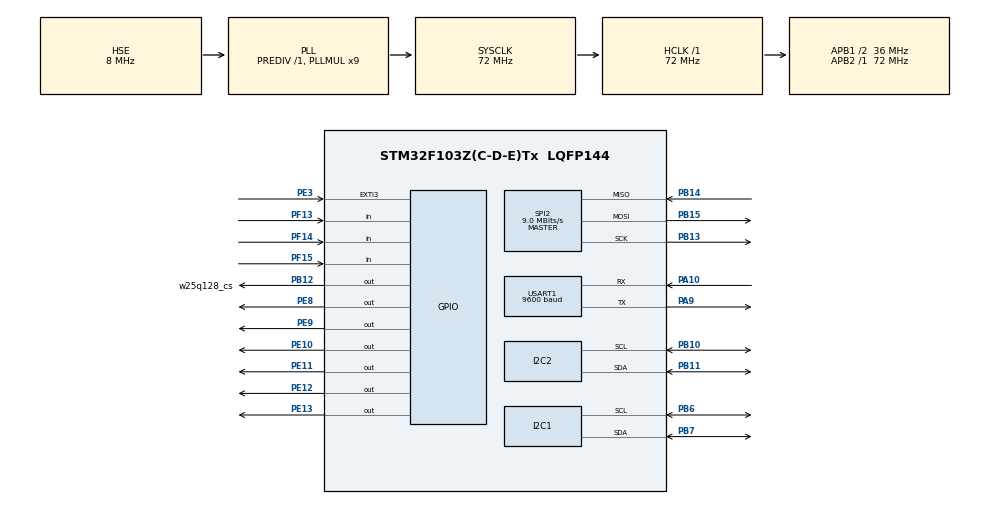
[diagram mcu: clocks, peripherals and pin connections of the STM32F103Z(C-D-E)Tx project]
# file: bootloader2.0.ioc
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Mcu.Family=STM32F1
Mcu.Name=STM32F103Z(C-D-E)Tx
Mcu.Package=LQFP144
NVIC.EXTI3_IRQn=true\:0\:0\:false\:false\:true\:true\:true\:true
NVIC.PriorityGroup=NVIC_PRIORITYGROUP_4
NVIC.TIM4_IRQn=true\:0\:0\:false\:false\:true\:true\:true\:true
NVIC.TIM7_IRQn=true\:15\:0\:false\:false\:true\:false\:true\:true
NVIC.TimeBase=TIM7_IRQn
NVIC.TimeBaseIP=TIM7
NVIC.USART1_IRQn=true\:0\:0\:false\:false\:true\:true\:true\:true
OSC_IN.Mode=HSE-External-Oscillator
OSC_IN.Signal=RCC_OSC_IN
OSC_OUT.Mode=HSE-External-Oscillator
OSC_OUT.Signal=RCC_OSC_OUT
PA10.Mode=Asynchronous
PA10.Signal=USART1_RX
PA13.Mode=JTAG_4_pins
PA13.Signal=SYS_JTMS-SWDIO
PA14.Mode=JTAG_4_pins
PA14.Signal=SYS_JTCK-SWCLK
PA15.Mode=JTAG_4_pins
PA15.Signal=SYS_JTDI
PA9.Mode=Asynchronous
PA9.Signal=USART1_TX
PB10.Mode=I2C
PB10.Signal=I2C2_SCL
PB11.Mode=I2C
PB11.Signal=I2C2_SDA
PB12.GPIO_Label=w25q128_cs
PB12.GPIO_Speed=GPIO_SPEED_FREQ_HIGH
PB12.PinState=GPIO_PIN_SET
PB12.Signal=GPIO_Output
PB13.Mode=Full_Duplex_Master
PB13.Signal=SPI2_SCK
PB14.Mode=Full_Duplex_Master
PB14.Signal=SPI2_MISO
PB15.Mode=Full_Duplex_Master
PB15.Signal=SPI2_MOSI
PB3.Mode=JTAG_4_pins
PB3.Signal=SYS_JTDO-TRACESWO
PB6.Mode=I2C
PB6.Signal=I2C1_SCL
PB7.Mode=I2C
PB7.Signal=I2C1_SDA
PC14-OSC32_IN.Mode=LSE-External-Oscillator
PC14-OSC32_IN.Signal=RCC_OSC32_IN
PC15-OSC32_OUT.Mode=LSE-External-Oscillator
PC15-OSC32_OUT.Signal=RCC_OSC32_OUT
PE10.GPIO_Speed=GPIO_SPEED_FREQ_HIGH
PE10.Signal=GPIO_Output
PE11.GPIO_Speed=GPIO_SPEED_FREQ_HIGH
PE11.Signal=GPIO_Output
PE12.GPIO_Speed=GPIO_SPEED_FREQ_HIGH
PE12.Signal=GPIO_Output
PE13.GPIO_Speed=GPIO_SPEED_FREQ_HIGH
PE13.PinState=GPIO_PIN_SET
PE13.Signal=GPIO_Output
PE3.GPIO_ModeDefaultEXTI=GPIO_MODE_IT_FALLING
PE3.GPIO_PuPd=GPIO_PULLUP
PE3.Signal=GPXTI3
PE8.GPIO_Speed=GPIO_SPEED_FREQ_HIGH
PE8.Signal=GPIO_Output
PE9.GPIO_Speed=GPIO_SPEED_FREQ_HIGH
PE9.Signal=GPIO_Output
PF13.GPIO_PuPd=GPIO_PULLUP
PF13.Signal=GPIO_Input
PF14.GPIO_PuPd=GPIO_PULLUP
PF14.Signal=GPIO_Input
PF15.GPIO_PuPd=GPIO_PULLUP
PF15.Signal=GPIO_Input
ProjectManager.HeapSize=0x200
ProjectManager.StackSize=0x400
ProjectManager.TargetToolchain=MDK-ARM V5
RCC.AHBFreq_Value=72000000
RCC.APB1CLKDivider=RCC_HCLK_DIV2
RCC.APB1Freq_Value=36000000
RCC.APB1TimFreq_Value=72000000
RCC.APB2Freq_Value=72000000
RCC.APB2TimFreq_Value=72000000
RCC.HCLKFreq_Value=72000000
RCC.PLLMUL=RCC_PLL_MUL9
RCC.PLLSourceVirtual=RCC_PLLSOURCE_HSE
RCC.SYSCLKFreq_VALUE=72000000
RCC.SYSCLKSource=RCC_SYSCLKSOURCE_PLLCLK
RCC.USBFreq_Value=72000000
SPI2.BaudRatePrescaler=SPI_BAUDRATEPRESCALER_4
SPI2.CalculateBaudRate=9.0 MBits/s
SPI2.Direction=SPI_DIRECTION_2LINES
SPI2.Mode=SPI_MODE_MASTER
SPI2.VirtualType=VM_MASTER
TIM4.Prescaler=71
USART1.BaudRate=9600
USART1.VirtualMode=VM_ASYNC
VP_CRC_VS_CRC.Mode=CRC_Activate
VP_SYS_VS_tim7.Mode=TIM7
VP_TIM4_VS_ClockSourceINT.Mode=Internal
board=custom

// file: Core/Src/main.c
/* USER CODE BEGIN Header */
/**
  ******************************************************************************
  * @file           : main.c
  * @brief          : Main program body
  ******************************************************************************
  * @attention
  *
  * Copyright (c) 2026 STMicroelectronics.
  * All rights reserved.
  *
  * This software is licensed under terms that can be found in the LICENSE file
  * in the root directory of this software component.
  * If no LICENSE file comes with this software, it is provided AS-IS.
  *
  ******************************************************************************
  */
/* USER CODE END Header */
#include "main.h"
#include "crc.h"
#include "i2c.h"
#include "spi.h"
#include "tim.h"
#include "usart.h"
#include "gpio.h"

/* USER CODE BEGIN Includes */
#include "App_bootloader.h"
#include "w25q128.h"
#include "gui.h"
extern uint16_t uart_rec_full_len;

/* USER CODE END Includes */

void SystemClock_Config(void);

int main(void)
{

  /* MCU Configuration--------------------------------------------------------*/

  /* Reset of all peripherals, Initializes the Flash interface and the Systick. */
  HAL_Init();

  /* USER CODE BEGIN Init */
		__disable_irq();
    SCB->VTOR = UPDATA_START_ADDR;
		__enable_irq();
  /* USER CODE END Init */

  /* Configure the system clock */
  SystemClock_Config();

  /* Initialize all configured peripherals */
  MX_GPIO_Init();
  MX_USART1_UART_Init();
  MX_SPI2_Init();
  MX_I2C2_Init();
  MX_I2C1_Init();
  MX_TIM4_Init();
  MX_CRC_Init();
  /* USER CODE BEGIN 2 */
  // updata_val data;
  // data.BOOT_UPDATE_FLAG = BOOT_HAVE_NEW_DATA;
  // w24c02_write_bytes(CHECK_UPDATE_ADDR, (uint8_t *)&data, sizeof(data));
  HAL_Delay(5000);

  /* USER CODE END 2 */

  /* Infinite loop */
  while (1)
  {
    app_bootloader_run();
  }
}

void SystemClock_Config(void)
{
  RCC_OscInitTypeDef RCC_OscInitStruct = {0};
  RCC_ClkInitTypeDef RCC_ClkInitStruct = {0};

  /** Initializes the RCC Oscillators according to the specified parameters
  * in the RCC_OscInitTypeDef structure.
  */
  RCC_OscInitStruct.OscillatorType = RCC_OSCILLATORTYPE_HSE;
  RCC_OscInitStruct.HSEState = RCC_HSE_ON;
  RCC_OscInitStruct.HSEPredivValue = RCC_HSE_PREDIV_DIV1;
  RCC_OscInitStruct.HSIState = RCC_HSI_ON;
  RCC_OscInitStruct.PLL.PLLState = RCC_PLL_ON;
  RCC_OscInitStruct.PLL.PLLSource = RCC_PLLSOURCE_HSE;
  RCC_OscInitStruct.PLL.PLLMUL = RCC_PLL_MUL9;
  if (HAL_RCC_OscConfig(&RCC_OscInitStruct) != HAL_OK)
  {
    Error_Handler();
  }

  /** Initializes the CPU, AHB and APB buses clocks
  */
  RCC_ClkInitStruct.ClockType = RCC_CLOCKTYPE_HCLK|RCC_CLOCKTYPE_SYSCLK
                              |RCC_CLOCKTYPE_PCLK1|RCC_CLOCKTYPE_PCLK2;
  RCC_ClkInitStruct.SYSCLKSource = RCC_SYSCLKSOURCE_PLLCLK;
  RCC_ClkInitStruct.AHBCLKDivider = RCC_SYSCLK_DIV1;
  RCC_ClkInitStruct.APB1CLKDivider = RCC_HCLK_DIV2;
  RCC_ClkInitStruct.APB2CLKDivider = RCC_HCLK_DIV1;

  if (HAL_RCC_ClockConfig(&RCC_ClkInitStruct, FLASH_LATENCY_2) != HAL_OK)
  {
    Error_Handler();
  }
}

void HAL_TIM_PeriodElapsedCallback(TIM_HandleTypeDef *htim)
{
  if (htim->Instance == TIM7) {
    HAL_IncTick();
  }
  /* USER CODE BEGIN Callback 1 */
 if (htim->Instance == TIM4)
  {
    if (g_delay_us_done == 0)
    {
      g_delay_us_done = 1;
    }

    if (g_delay_ms_done == 0)
    {
      g_delay_ms_done = 1;
    }
    HAL_TIM_Base_Stop_IT(&htim4);
	}
  /* USER CODE END Callback 1 */
}

void Error_Handler(void)
{
  __disable_irq();
  while (1)
  {
  }
}
